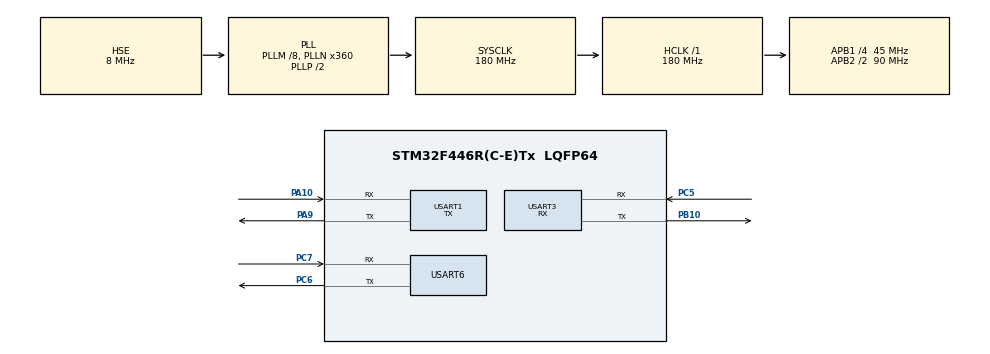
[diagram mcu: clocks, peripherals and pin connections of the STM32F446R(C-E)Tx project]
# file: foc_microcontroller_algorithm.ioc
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Mcu.Family=STM32F4
Mcu.Name=STM32F446R(C-E)Tx
Mcu.Package=LQFP64
NVIC.PriorityGroup=NVIC_PRIORITYGROUP_4
PA10.Mode=Asynchronous
PA10.Signal=USART1_RX
PA13.Mode=Serial_Wire
PA13.Signal=SYS_JTMS-SWDIO
PA14.Mode=Serial_Wire
PA14.Signal=SYS_JTCK-SWCLK
PA9.Mode=Asynchronous
PA9.Signal=USART1_TX
PB10.Mode=Asynchronous
PB10.Signal=USART3_TX
PC5.Mode=Asynchronous
PC5.Signal=USART3_RX
PC6.Mode=Asynchronous
PC6.Signal=USART6_TX
PC7.Mode=Asynchronous
PC7.Signal=USART6_RX
PH0-OSC_IN.Mode=HSE-External-Oscillator
PH0-OSC_IN.Signal=RCC_OSC_IN
PH1-OSC_OUT.Mode=HSE-External-Oscillator
PH1-OSC_OUT.Signal=RCC_OSC_OUT
ProjectManager.HeapSize=0x200
ProjectManager.StackSize=0x400
ProjectManager.TargetToolchain=STM32CubeIDE
RCC.AHBFreq_Value=180000000
RCC.APB1CLKDivider=RCC_HCLK_DIV4
RCC.APB1Freq_Value=45000000
RCC.APB1TimFreq_Value=90000000
RCC.APB2CLKDivider=RCC_HCLK_DIV2
RCC.APB2Freq_Value=90000000
RCC.APB2TimFreq_Value=180000000
RCC.CortexFreq_Value=180000000
RCC.HCLKFreq_Value=180000000
RCC.HSE_VALUE=8000000
RCC.PLLM=8
RCC.PLLN=360
RCC.PLLSourceVirtual=RCC_PLLSOURCE_HSE
RCC.SYSCLKFreq_VALUE=180000000
RCC.SYSCLKSource=RCC_SYSCLKSOURCE_PLLCLK
RCC.USBFreq_Value=180000000
RCC.VCOOutputFreq_Value=360000000
USART1.Mode=MODE_TX
USART1.VirtualMode=VM_ASYNC
USART3.Mode=MODE_RX
USART3.VirtualMode=VM_ASYNC
USART6.VirtualMode=VM_ASYNC
board=custom

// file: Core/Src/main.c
/* USER CODE BEGIN Header */
/* USER CODE END Header */
#include "main.h"
#include "usart.h"
#include "gpio.h"

/* USER CODE BEGIN Includes */
/* USER CODE BEGIN Includes */
#include <math.h>
#include <string.h>
#include <stdio.h>
#include "foc.h"
/* USER CODE END Includes */
/* USER CODE END Includes */

/* USER CODE BEGIN PD */
/* USER CODE BEGIN PD */
#define DT  0.002f    /* ~2ms actual loop period */   /* 0.1 ms control period          */

/* USER CODE END PD */
/* USER CODE END PD */

/* USER CODE BEGIN PV */
/* USER CODE BEGIN PV */
static FOC_Handle_t  hfoc;

static uint8_t rx_buf[12];   /* 3 floats: Ia, Ib, theta */
static uint8_t  tx_buf[12];   /* 3 floats: Va, Vb, Vc to motor MCU */
static char     dbg_buf[64];  /* ASCII string for TeraTerm        */

/* USER CODE END PV */
/* USER CODE END PV */

void SystemClock_Config(void);

int main(void)
{

  /* MCU Configuration--------------------------------------------------------*/

  /* Reset of all peripherals, Initializes the Flash interface and the Systick. */
  HAL_Init();

  /* Configure the system clock */
  SystemClock_Config();

  /* Initialize all configured peripherals */
  MX_GPIO_Init();
  MX_USART1_UART_Init();
  MX_USART3_UART_Init();
  MX_USART6_UART_Init();
  /* USER CODE BEGIN 2 */
  FOC_Init(&hfoc, 0.0f, 10.0f, 1.0f, 0.0f, -48.0f, 48.0f);
  //                           Kp    Ki=0 → pure P controller

  /* Send initial Va=Vb=Vc=0 to start the chain */

  char *boot_msg = "FOC MCU Ready\r\n";
  HAL_UART_Transmit(&huart6, (uint8_t *)boot_msg, strlen(boot_msg), 100);
  /* USER CODE END 2 */

  /* USER CODE BEGIN WHILE */
  while (1)
  {
	  HAL_UART_Receive(&huart3, rx_buf, 12, HAL_MAX_DELAY);

	  float ia, ib, theta;
	  memcpy(&ia,    &rx_buf[0], 4);
	  memcpy(&ib,    &rx_buf[4], 4);
	  memcpy(&theta, &rx_buf[8], 4);

	  FOC_Step(&hfoc, ia, ib, theta, DT);   /* only ONE call */

	  float va = hfoc.inv_clarke_out.a;
	  float vb = hfoc.inv_clarke_out.b;
	  float vc = hfoc.inv_clarke_out.c;
	  float vd = hfoc.pi_out.d;   // ✓ actual vd output
	  float vq = hfoc.pi_out.q;   // ✓ actual vq output

	  memcpy(&tx_buf[0], &va, 4);
	  memcpy(&tx_buf[4], &vb, 4);
	  memcpy(&tx_buf[8], &vc, 4);
	  HAL_UART_Transmit(&huart1, tx_buf, 12, HAL_MAX_DELAY);

	  int len = snprintf(dbg_buf, sizeof(dbg_buf),
	                     "Va=%.3f Vb=%.3f Vc=%.3f Vd=%.3f Vq=%.3f\r\n", va, vb, vc, vd, vq);
	  HAL_UART_Transmit(&huart6, (uint8_t *)dbg_buf, len, 50);
  }
  /* USER CODE END 3 */
}

void SystemClock_Config(void)
{
  RCC_OscInitTypeDef RCC_OscInitStruct = {0};
  RCC_ClkInitTypeDef RCC_ClkInitStruct = {0};

  /** Configure the main internal regulator output voltage
  */
  __HAL_RCC_PWR_CLK_ENABLE();
  __HAL_PWR_VOLTAGESCALING_CONFIG(PWR_REGULATOR_VOLTAGE_SCALE1);

  /** Initializes the RCC Oscillators according to the specified parameters
  * in the RCC_OscInitTypeDef structure.
  */
  RCC_OscInitStruct.OscillatorType = RCC_OSCILLATORTYPE_HSE;
  RCC_OscInitStruct.HSEState = RCC_HSE_ON;
  RCC_OscInitStruct.PLL.PLLState = RCC_PLL_ON;
  RCC_OscInitStruct.PLL.PLLSource = RCC_PLLSOURCE_HSE;
  RCC_OscInitStruct.PLL.PLLM = 8;
  RCC_OscInitStruct.PLL.PLLN = 360;
  RCC_OscInitStruct.PLL.PLLP = RCC_PLLP_DIV2;
  RCC_OscInitStruct.PLL.PLLQ = 2;
  RCC_OscInitStruct.PLL.PLLR = 2;
  if (HAL_RCC_OscConfig(&RCC_OscInitStruct) != HAL_OK)
  {
    Error_Handler();
  }

  /** Activate the Over-Drive mode
  */
  if (HAL_PWREx_EnableOverDrive() != HAL_OK)
  {
    Error_Handler();
  }

  /** Initializes the CPU, AHB and APB buses clocks
  */
  RCC_ClkInitStruct.ClockType = RCC_CLOCKTYPE_HCLK|RCC_CLOCKTYPE_SYSCLK
                              |RCC_CLOCKTYPE_PCLK1|RCC_CLOCKTYPE_PCLK2;
  RCC_ClkInitStruct.SYSCLKSource = RCC_SYSCLKSOURCE_PLLCLK;
  RCC_ClkInitStruct.AHBCLKDivider = RCC_SYSCLK_DIV1;
  RCC_ClkInitStruct.APB1CLKDivider = RCC_HCLK_DIV4;
  RCC_ClkInitStruct.APB2CLKDivider = RCC_HCLK_DIV2;

  if (HAL_RCC_ClockConfig(&RCC_ClkInitStruct, FLASH_LATENCY_5) != HAL_OK)
  {
    Error_Handler();
  }
}

void Error_Handler(void)
{
}
